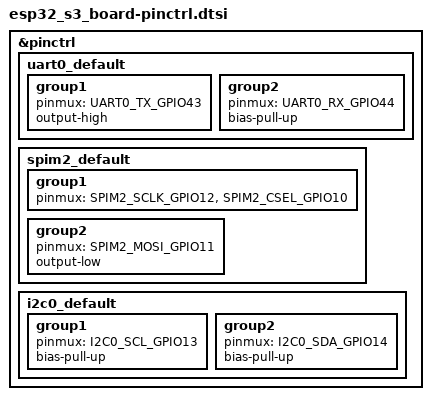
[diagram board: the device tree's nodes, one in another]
#include <zephyr/dt-bindings/pinctrl/esp32s3-pinctrl.h>

&pinctrl {
    uart0_default: uart0_default {
        group1 {
            pinmux = <UART0_TX_GPIO43>;
            output-high;
        };
        group2 {
            pinmux = <UART0_RX_GPIO44>;
            bias-pull-up;
        };
    };

    spim2_default: spim2_default {
        group1 {
            pinmux = <SPIM2_SCLK_GPIO12>, <SPIM2_CSEL_GPIO10>;
        };
        group2 {
            pinmux = <SPIM2_MOSI_GPIO11>;
            output-low;
        };
    };

    i2c0_default: i2c0_default {
        group1 {
            pinmux = <I2C0_SCL_GPIO13>;
            bias-pull-up;
        };
        group2 {
            pinmux = <I2C0_SDA_GPIO14>;
            bias-pull-up;
        };
    };
};
